# MKV31F51212 register map
Vendor: Freescale Semiconductor, Inc.; Series: Kinetis_V; File version: 1.6
CPU: CM4 r0p1, little endian, no MPU, FPU, VTOR, 4 interrupt priority bits
Registers are 32-bit, read-write, reset 0x0 unless marked. A register's access mark holds for its fields unless they carry their own. Offsets are from the block's base; [hi:lo] are bit positions; {n}, {i} and the like mark numbered series; 'fields as' and 'values as' point back to an identical list.

## RFSYS — System register file
Base 0x40041000; register names take the prefix RFSYS_
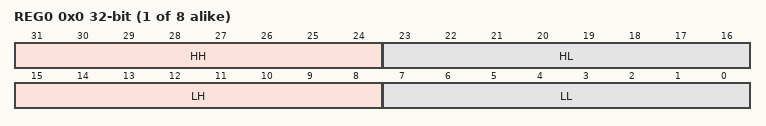
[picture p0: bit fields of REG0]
{0x0+4i} REG{i} (i=0..7) — Register file register
  [31:24] HH, [23:16] HL, [15:8] LH, [7:0] LL

## PORTA — Pin Control and Interrupts
Base 0x40049000; register names take the prefix PORTA_
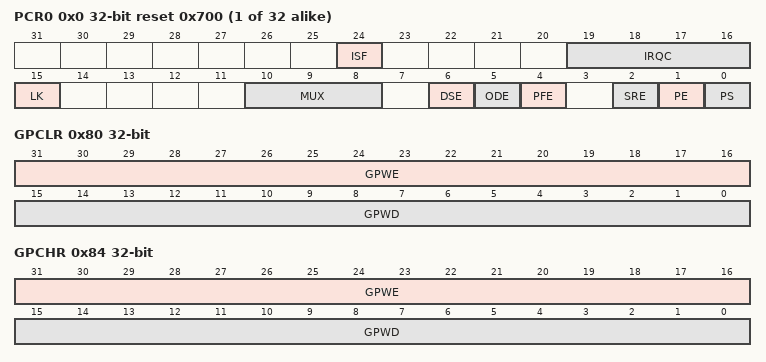
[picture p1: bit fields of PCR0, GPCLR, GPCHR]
{0x0+4i} PCR{i} (i=0..31) reset 0x700 — Pin Control Register n
  [24] ISF — Interrupt Status Flag
    0=Configured interrupt is not detected; 1=Configured interrupt is detected. If the pin is configured to generate a DMA request, then the corresponding flag will be cleared automatically at the completion of the requested DMA transfer. Otherwise, the flag remains set until a logic 1 is written to the flag. If the pin is configured for a level sensitive interrupt and the pin remains asserted, then the flag is set again immediately after it is cleared.
  [19:16] IRQC — Interrupt Configuration
    0=Interrupt/DMA request disabled; 1=DMA request on rising edge; 2=DMA request on falling edge; 3=DMA request on either edge; 8=Interrupt when logic 0; 9=Interrupt on rising-edge; 10=Interrupt on falling-edge; 11=Interrupt on either edge; 12=Interrupt when logic 1
  [15] LK — Lock Register
    0=Pin Control Register fields [15:0] are not locked; 1=Pin Control Register fields [15:0] are locked and cannot be updated until the next system reset
  [10:8] MUX — Pin Mux Control
    0=Pin disabled (analog); 1=Alternative 1 (GPIO); {v}=Alternative {v} (chip-specific) (v=2..7)
  [6] DSE — Drive Strength Enable
    0=Low drive strength is configured on the corresponding pin, if pin is configured as a digital output; 1=High drive strength is configured on the corresponding pin, if pin is configured as a digital output
  [5] ODE — Open Drain Enable
    0=Open drain output is disabled on the corresponding pin; 1=Open drain output is enabled on the corresponding pin, if the pin is configured as a digital output
  [4] PFE — Passive Filter Enable
    0=Passive input filter is disabled on the corresponding pin; 1=Passive input filter is enabled on the corresponding pin, if the pin is configured as a digital input. Refer to the device data sheet for filter characteristics.
  [2] SRE — Slew Rate Enable
    0=Fast slew rate is configured on the corresponding pin, if the pin is configured as a digital output; 1=Slow slew rate is configured on the corresponding pin, if the pin is configured as a digital output
  [1] PE — Pull Enable
    0=Internal pullup or pulldown resistor is not enabled on the corresponding pin; 1=Internal pullup or pulldown resistor is enabled on the corresponding pin, if the pin is configured as a digital input
  [0] PS — Pull Select
    0=Internal pulldown resistor is enabled on the corresponding pin, if the corresponding PE field is set; 1=Internal pullup resistor is enabled on the corresponding pin, if the corresponding PE field is set
0x80 GPCLR wo — Global Pin Control Low Register
  [31:16] GPWE — Global Pin Write Enable
    0=Corresponding Pin Control Register is not updated with the value in GPWD; 1=Corresponding Pin Control Register is updated with the value in GPWD
  [15:0] GPWD — Global Pin Write Data
0x84 GPCHR wo — Global Pin Control High Register
  fields as GPCLR
0xA0 ISFR — Interrupt Status Flag Register
  [31:0] ISF — Interrupt Status Flag
    values as PCR0.ISF

## WDOG — Generation 2008 Watchdog Timer
Base 0x40052000; register names take the prefix WDOG_
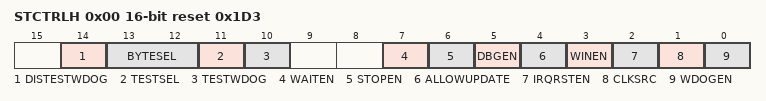
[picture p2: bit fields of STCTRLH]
0x00 STCTRLH 16-bit reset 0x1D3 — Watchdog Status and Control Register High
  [14] DISTESTWDOG
    0=WDOG functional test mode is not disabled; 1=WDOG functional test mode is disabled permanently until reset
  [13:12] BYTESEL
    {v}=Byte {v} selected (v=0..3)
  [11] TESTSEL
    0=Quick test. The timer runs in normal operation. You can load a small time-out value to do a quick test.; 1=Byte test. Puts the timer in the byte test mode where individual bytes of the timer are enabled for operation and are compared for time-out against the corresponding byte of the programmed time-out value. Select the byte through BYTESEL[1:0] for testing.
  [10] TESTWDOG
  [7] WAITEN
    0=WDOG is disabled in CPU Wait mode; 1=WDOG is enabled in CPU Wait mode
  [6] STOPEN
    0=WDOG is disabled in CPU Stop mode; 1=WDOG is enabled in CPU Stop mode
  [5] DBGEN
    0=WDOG is disabled in CPU Debug mode; 1=WDOG is enabled in CPU Debug mode
  [4] ALLOWUPDATE
    0=No further updates allowed to WDOG write-once registers; 1=WDOG write-once registers can be unlocked for updating
  [3] WINEN
    0=Windowing mode is disabled; 1=Windowing mode is enabled
  [2] IRQRSTEN
    0=WDOG time-out generates reset only; 1=WDOG time-out initially generates an interrupt. After WCT, it generates a reset.
  [1] CLKSRC
    0=WDOG clock sourced from LPO ; 1=WDOG clock sourced from alternate clock source
  [0] WDOGEN
    0=WDOG is disabled; 1=WDOG is enabled
0x02 STCTRLL 16-bit reset 0x1 — Watchdog Status and Control Register Low
  [15] INTFLG
0x04 TOVALH 16-bit reset 0x4C — Watchdog Time-out Value Register High
  [15:0] TOVALHIGH
0x06 TOVALL 16-bit reset 0x4B4C — Watchdog Time-out Value Register Low
  [15:0] TOVALLOW
0x08 WINH 16-bit — Watchdog Window Register High
  [15:0] WINHIGH
0x0A WINL 16-bit reset 0x10 — Watchdog Window Register Low
  [15:0] WINLOW
0x0C REFRESH 16-bit reset 0xB480 — Watchdog Refresh register
  [15:0] WDOGREFRESH
0x0E UNLOCK 16-bit reset 0xD928 — Watchdog Unlock register
  [15:0] WDOGUNLOCK
0x10 TMROUTH 16-bit — Watchdog Timer Output Register High
  [15:0] TIMEROUTHIGH
0x12 TMROUTL 16-bit — Watchdog Timer Output Register Low
  [15:0] TIMEROUTLOW
0x14 RSTCNT 16-bit — Watchdog Reset Count register
0x16 PRESC 16-bit reset 0x400 — Watchdog Prescaler register
  [10:8] PRESCVAL

## Notices in the file
Redistribution and use in source and binary forms, with or without modification,
are permitted provided that the following conditions are met:
o Redistributions of source code must retain the above copyright notice, this list
of conditions and the following disclaimer.
o Redistributions in binary form must reproduce the above copyright notice, this
list of conditions and the following disclaimer in the documentation and/or
other materials provided with the distribution.
o Neither the name of Freescale Semiconductor, Inc. nor the names of its
contributors may be used to endorse or promote products derived from this
software without specific prior written permission.
THIS SOFTWARE IS PROVIDED BY THE COPYRIGHT HOLDERS AND CONTRIBUTORS "AS IS" AND
ANY EXPRESS OR IMPLIED WARRANTIES, INCLUDING, BUT NOT LIMITED TO, THE IMPLIED
WARRANTIES OF MERCHANTABILITY AND FITNESS FOR A PARTICULAR PURPOSE ARE
DISCLAIMED. IN NO EVENT SHALL THE COPYRIGHT HOLDER OR CONTRIBUTORS BE LIABLE FOR
ANY DIRECT, INDIRECT, INCIDENTAL, SPECIAL, EXEMPLARY, OR CONSEQUENTIAL DAMAGES
(INCLUDING, BUT NOT LIMITED TO, PROCUREMENT OF SUBSTITUTE GOODS OR SERVICES;
LOSS OF USE, DATA, OR PROFITS; OR BUSINESS INTERRUPTION) HOWEVER CAUSED AND ON
ANY THEORY OF LIABILITY, WHETHER IN CONTRACT, STRICT LIABILITY, OR TORT
(INCLUDING NEGLIGENCE OR OTHERWISE) ARISING IN ANY WAY OUT OF THE USE OF THIS
SOFTWARE, EVEN IF ADVISED OF THE POSSIBILITY OF SUCH DAMAGE.
